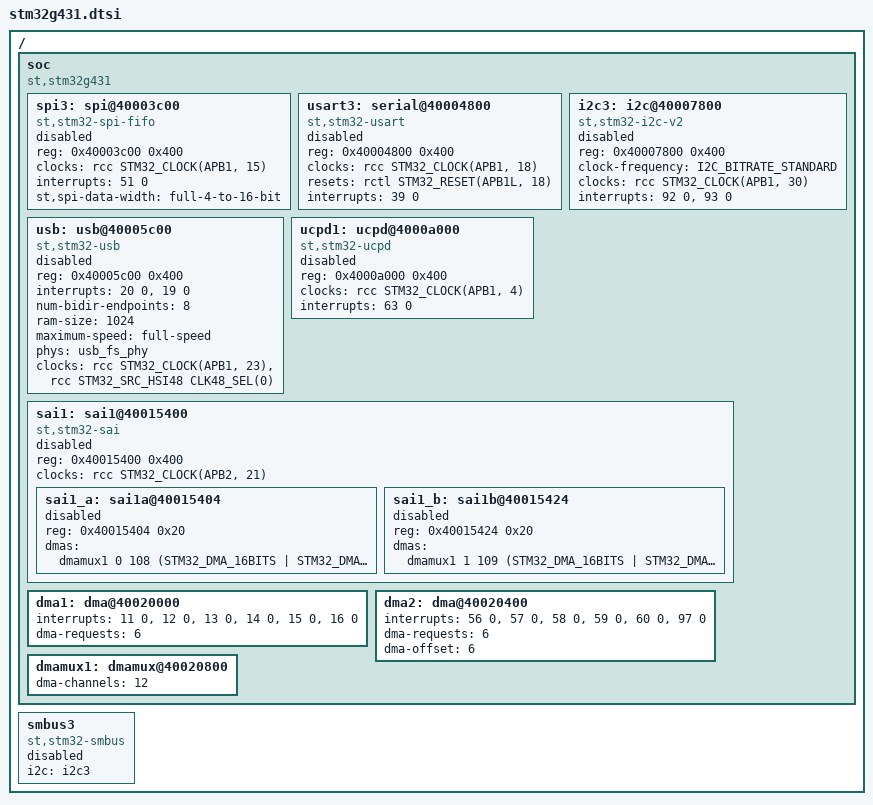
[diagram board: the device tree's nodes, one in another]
/*
 * Copyright (c) 2019 Richard Osterloh <richard.osterloh@gmail.com>
 *
 * SPDX-License-Identifier: Apache-2.0
 */

#include <st/g4/stm32g4.dtsi>

/ {
	soc {
		compatible = "st,stm32g431", "st,stm32g4", "simple-bus";

		spi3: spi@40003c00 {
			compatible = "st,stm32-spi-fifo", "st,stm32-spi";
			reg = <0x40003c00 0x400>;
			#address-cells = <1>;
			#size-cells = <0>;
			clocks = <&rcc STM32_CLOCK(APB1, 15)>;
			interrupts = <51 0>;
			st,spi-data-width = "full-4-to-16-bit";
			status = "disabled";
		};

		usart3: serial@40004800 {
			compatible = "st,stm32-usart", "st,stm32-uart";
			reg = <0x40004800 0x400>;
			clocks = <&rcc STM32_CLOCK(APB1, 18)>;
			resets = <&rctl STM32_RESET(APB1L, 18)>;
			interrupts = <39 0>;
			status = "disabled";
		};

		i2c3: i2c@40007800 {
			compatible = "st,stm32-i2c-v2";
			reg = <0x40007800 0x400>;
			clock-frequency = <I2C_BITRATE_STANDARD>;
			#address-cells = <1>;
			#size-cells = <0>;
			clocks = <&rcc STM32_CLOCK(APB1, 30)>;
			interrupts = <92 0>, <93 0>;
			interrupt-names = "event", "error";
			status = "disabled";
		};

		usb: usb@40005c00 {
			compatible = "st,stm32-usb";
			reg = <0x40005c00 0x400>;
			interrupts = <20 0>, <19 0>;
			interrupt-names = "usb", "usbhp";
			num-bidir-endpoints = <8>;
			ram-size = <1024>;
			maximum-speed = "full-speed";
			phys = <&usb_fs_phy>;
			clocks = <&rcc STM32_CLOCK(APB1, 23)>,
				 <&rcc STM32_SRC_HSI48 CLK48_SEL(0)>;
			status = "disabled";
		};

		ucpd1: ucpd@4000a000 {
			compatible = "st,stm32-ucpd";
			reg = <0x4000a000 0x400>;
			clocks = <&rcc STM32_CLOCK(APB1, 4)>;
			interrupts = <63 0>;
			status = "disabled";
		};

		sai1: sai1@40015400 {
			compatible = "st,stm32-sai";
			reg = <0x40015400 0x400>;
			ranges;
			#address-cells = <1>;
			#size-cells = <1>;
			clocks = <&rcc STM32_CLOCK(APB2, 21)>;
			clock-names = "sai_ck";
			status = "disabled";

			sai1_a: sai1a@40015404 {
				reg = <0x40015404 0x20>;
				dmas = <&dmamux1 0 108
					(STM32_DMA_16BITS | STM32_DMA_PRIORITY_HIGH)>;
				#address-cells = <1>;
				#size-cells = <0>;
				status = "disabled";
			};

			sai1_b: sai1b@40015424 {
				reg = <0x40015424 0x20>;
				dmas = <&dmamux1 1 109
					(STM32_DMA_16BITS | STM32_DMA_PRIORITY_HIGH)>;
				#address-cells = <1>;
				#size-cells = <0>;
				status = "disabled";
			};
		};

		dma1: dma@40020000 {
			interrupts = <11 0>, <12 0>, <13 0>, <14 0>, <15 0>, <16 0>;
			dma-requests = <6>;
		};

		dma2: dma@40020400 {
			interrupts = <56 0>, <57 0>, <58 0>, <59 0>, <60 0>, <97 0>;
			dma-requests = <6>;
			dma-offset = <6>;
		};

		dmamux1: dmamux@40020800 {
			dma-channels = <12>;
		};
	};

	smbus3: smbus3 {
		compatible = "st,stm32-smbus";
		#address-cells = <1>;
		#size-cells = <0>;
		i2c = <&i2c3>;
		status = "disabled";
	};
};
